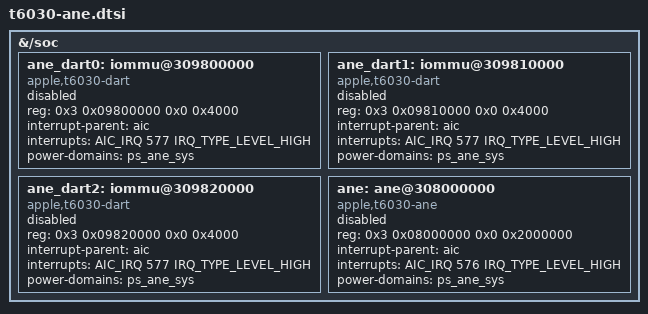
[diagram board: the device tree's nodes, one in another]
// SPDX-License-Identifier: GPL-2.0+ OR MIT
/*
 * Apple Neural Engine on the T6030 "M3 Pro" (H15, 16 cores).
 * Stage 2 draft of the ane-linux plan: engine window, interrupt, power
 * domain and DARTs. Include it at the end of t6030.dtsi, after
 * t6030-pmgr.dtsi.
 *
 * Source: macOS ADT nodes ane@F8000000 and dart-ane@F9800000. The
 * arm-io ranges add 0x2_1000_0000 to every ADT reg address.
 *
 * Power: the ADT power gate 0x1a4 is "ANE-SYS-V". The ADT PMGR device
 * table marks it virtual (flag 0x10) with parent ANE_SYS (0x82). ANE_SYS
 * is the only ANE entry with a real power-state register: PMGR +0x498,
 * which is ps_ane_sys. ANE_MPM, ANE_CPU, ANE_TD and ANE_BASE are also
 * virtual on T6030, so they get no Linux domain. Do not add domains at
 * PMGR +0xc000: that block has no ANE power-state register on T6030.
 *
 * The ADT ane node has five more reg windows. All five are PMGR
 * windows that macOS uses for direct power control:
 *   0x3_5070_0000 0x18000, 0x3_5072_4000 0x4000,
 *   0x3_503c_0000 0x24000, 0x2_1100_0000 0xf74000,
 *   0x3_642c_8000 0x4000.
 * Linux leaves them out: genpd owns PMGR.
 */

&{/soc} {
	/*
	 * ADT dart-ane: dart,t8110, dart-id 0x1d, sid-count 16 (SID 15 is
	 * bypass), page-size 0x4000, vm-base 0x100_0000_0000, vm-size
	 * 0x300_0000_0000. Four instances: DART 0 (LLT), DART 1 (BRD),
	 * DART 2 (BWR) and DAPF 0 (LLT) at 0x3_0980_4000. The ADT gives the
	 * DART no power gate; ps_ane_sys is an assumption.
	 * Disabled until stage 2b.
	 */
	ane_dart0: iommu@309800000 {
		compatible = "apple,t6030-dart", "apple,t8110-dart";
		reg = <0x3 0x09800000 0x0 0x4000>;
		#iommu-cells = <1>;
		interrupt-parent = <&aic>;
		interrupts = <AIC_IRQ 577 IRQ_TYPE_LEVEL_HIGH>;
		power-domains = <&ps_ane_sys>;
		status = "disabled";
	};

	ane_dart1: iommu@309810000 {
		compatible = "apple,t6030-dart", "apple,t8110-dart";
		reg = <0x3 0x09810000 0x0 0x4000>;
		#iommu-cells = <1>;
		interrupt-parent = <&aic>;
		interrupts = <AIC_IRQ 577 IRQ_TYPE_LEVEL_HIGH>;
		power-domains = <&ps_ane_sys>;
		status = "disabled";
	};

	ane_dart2: iommu@309820000 {
		compatible = "apple,t6030-dart", "apple,t8110-dart";
		reg = <0x3 0x09820000 0x0 0x4000>;
		#iommu-cells = <1>;
		interrupt-parent = <&aic>;
		interrupts = <AIC_IRQ 577 IRQ_TYPE_LEVEL_HIGH>;
		power-domains = <&ps_ane_sys>;
		status = "disabled";
	};

	/*
	 * One interrupt (ADT 0x240). The ADT has pre-loaded = 1 and no
	 * firmware-name: iBoot loads the "anef" image. Stage 2 adds no
	 * iommus, no mailbox and no memory-region.
	 */
	ane: ane@308000000 {
		compatible = "apple,t6030-ane";
		reg = <0x3 0x08000000 0x0 0x2000000>;
		reg-names = "engine";
		interrupt-parent = <&aic>;
		interrupts = <AIC_IRQ 576 IRQ_TYPE_LEVEL_HIGH>;
		interrupt-names = "ane";
		power-domains = <&ps_ane_sys>;
		status = "disabled";
	};
};
